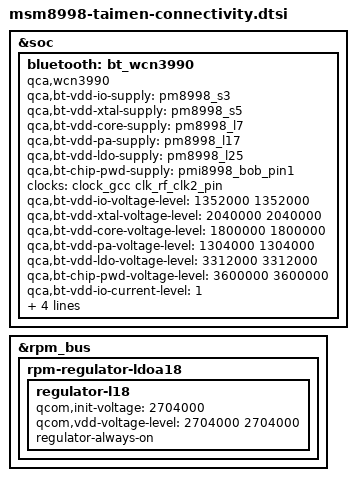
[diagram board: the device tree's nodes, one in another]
/* Copyright (c) 2017, The Linux Foundation. All rights reserved.
 *
 * This program is free software; you can redistribute it and/or modify
 * it under the terms of the GNU General Public License version 2 and
 * only version 2 as published by the Free Software Foundation.
 *
 * This program is distributed in the hope that it will be useful,
 * but WITHOUT ANY WARRANTY; without even the implied warranty of
 * MERCHANTABILITY or FITNESS FOR A PARTICULAR PURPOSE.  See the
 * GNU General Public License for more details.
 */

&soc {
	bluetooth: bt_wcn3990 {
		compatible = "qca,wcn3990";
		qca,bt-vdd-io-supply = <&pm8998_s3>;
		qca,bt-vdd-xtal-supply = <&pm8998_s5>;
		qca,bt-vdd-core-supply = <&pm8998_l7>;
		qca,bt-vdd-pa-supply = <&pm8998_l17>;
		qca,bt-vdd-ldo-supply = <&pm8998_l25>;
		qca,bt-chip-pwd-supply = <&pmi8998_bob_pin1>;
		clocks = <&clock_gcc clk_rf_clk2_pin>;
		clock-names = "rf_clk2";

		qca,bt-vdd-io-voltage-level = <1352000 1352000>;
		qca,bt-vdd-xtal-voltage-level = <2040000 2040000>;
		qca,bt-vdd-core-voltage-level = <1800000 1800000>;
		qca,bt-vdd-pa-voltage-level = <1304000 1304000>;
		qca,bt-vdd-ldo-voltage-level = <3312000 3312000>;
		qca,bt-chip-pwd-voltage-level = <3600000 3600000>;

		qca,bt-vdd-io-current-level = <1>; /* LPM/PFM */
		qca,bt-vdd-xtal-current-level = <1>; /* LPM/PFM */
		qca,bt-vdd-core-current-level = <1>; /* LPM/PFM */
		qca,bt-vdd-pa-current-level = <1>; /* LPM/PFM */
		qca,bt-vdd-ldo-current-level = <1>; /* LPM/PFM */
	};
};

&rpm_bus {
	rpm-regulator-ldoa18 {
		regulator-l18 {
			qcom,init-voltage = <2704000>;
			qcom,vdd-voltage-level = <2704000 2704000>;
			regulator-always-on;
		};
	};
};
